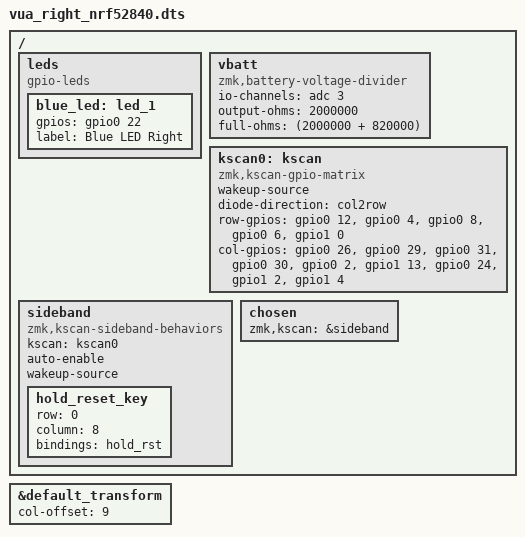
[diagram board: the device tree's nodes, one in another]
/*
 * Copyright (c) 2023 Deemen17
 * SPDX-License-Identifier: MIT
 */

#include "vua.dtsi"

/ {
    leds {
        compatible = "gpio-leds";
        blue_led: led_1 {
            gpios = <&gpio0 22 GPIO_ACTIVE_HIGH>;
            label = "Blue LED Right";
        };
    };

    vbatt: vbatt {
        compatible = "zmk,battery-voltage-divider";
        io-channels = <&adc 3>;
        output-ohms = <2000000>;
        full-ohms = <(2000000 + 820000)>;
    };

    kscan0: kscan {
        compatible = "zmk,kscan-gpio-matrix";
        wakeup-source;

        diode-direction = "col2row";

        row-gpios
            = <&gpio0 12 (GPIO_ACTIVE_HIGH | GPIO_PULL_DOWN)>
            , <&gpio0 4  (GPIO_ACTIVE_HIGH | GPIO_PULL_DOWN)>
            , <&gpio0 8  (GPIO_ACTIVE_HIGH | GPIO_PULL_DOWN)>
            , <&gpio0 6  (GPIO_ACTIVE_HIGH | GPIO_PULL_DOWN)>
            , <&gpio1 0  (GPIO_ACTIVE_HIGH | GPIO_PULL_DOWN)>
            ;

        col-gpios
            = <&gpio0 26 GPIO_ACTIVE_HIGH>
            , <&gpio0 29 GPIO_ACTIVE_HIGH>
            , <&gpio0 31 GPIO_ACTIVE_HIGH>
            , <&gpio0 30 GPIO_ACTIVE_HIGH>
            , <&gpio0 2  GPIO_ACTIVE_HIGH>
            , <&gpio1 13 GPIO_ACTIVE_HIGH>
            , <&gpio0 24 GPIO_ACTIVE_HIGH>
            , <&gpio1 2  GPIO_ACTIVE_HIGH>
            , <&gpio1 4  GPIO_ACTIVE_HIGH>
            ;
    };

    /*
     * Wraps the matrix so the top-right key (HOME, local row 0 / column 8) also
     * runs &hold_rst locally. This is the one that matters: the peripheral runs
     * no keymap, so without this there is no way to reset this half from its own
     * keys once it loses the central.
     */
    sideband: sideband {
        compatible = "zmk,kscan-sideband-behaviors";
        kscan = <&kscan0>;
        auto-enable;
        wakeup-source;

        hold_reset_key {
            row = <0>;
            column = <8>;
            bindings = <&hold_rst>;
        };
    };
};

/ {
    chosen {
        zmk,kscan = &sideband;
    };
};

&default_transform {
    col-offset = <9>;
};
